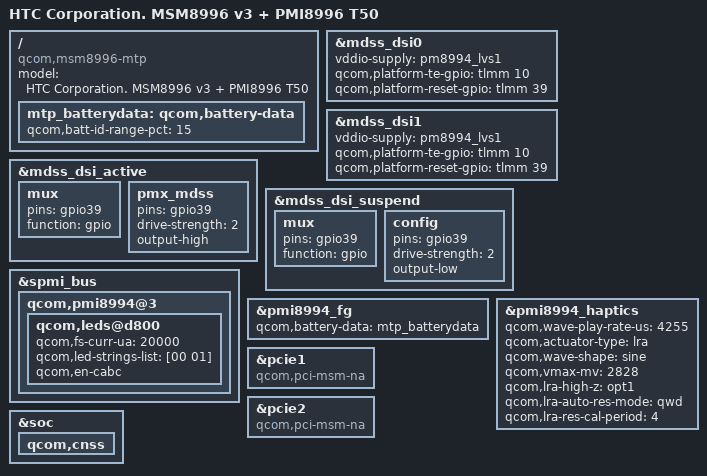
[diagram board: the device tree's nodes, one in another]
/* Copyright (c) 2015, The Linux Foundation. All rights reserved.
 *
 * This program is free software; you can redistribute it and/or modify
 * it under the terms of the GNU General Public License version 2 and
 * only version 2 as published by the Free Software Foundation.
 *
 * This program is distributed in the hope that it will be useful,
 * but WITHOUT ANY WARRANTY; without even the implied warranty of
 * MERCHANTABILITY or FITNESS FOR A PARTICULAR PURPOSE.  See the
 * GNU General Public License for more details.
 */


#include "msm8996-htc-common.dtsi"
#include "msm8996-htc-regulator.dtsi"
#include "msm8996-htc-pm.dtsi"
#include "dsi-panel-t50-hx8396c2.dtsi"
#include "dsi-panel-t50.dtsi"
#include "msm8996-touch-t50.dtsi"
#include "msm8996-key-t50.dtsi"
#include "msm8996-audio-t50.dtsi"
#include "msm8996-htc-led.dtsi"
#include "msm8996-camera-sensor-t50_xc.dtsi"
#include "msm8996-htc-nfc.dtsi"

/ {
	model = "HTC Corporation. MSM8996 v3 + PMI8996 T50";
	compatible = "qcom,msm8996-mtp", "qcom,msm8996", "qcom,mtp";
};

&mdss_dsi0 {
        vddio-supply = <&pm8994_lvs1>;

        qcom,platform-te-gpio = <&tlmm 10 0>;
        qcom,platform-reset-gpio = <&tlmm 39 0>;
        /delete-property/ qcom,platform-bklight-en-gpio;
};

&mdss_dsi1 {
        vddio-supply = <&pm8994_lvs1>;

        qcom,platform-te-gpio = <&tlmm 10 0>;
        qcom,platform-reset-gpio = <&tlmm 39 0>;
        /delete-property/ qcom,platform-bklight-en-gpio;
};

&mdss_dsi_active {
        mux {
                pins = "gpio39";
                function = "gpio";
        };

        pmx_mdss {
                pins = "gpio39";
                drive-strength = <2>; /* 2 mA */
                output-high;
        };
};

&mdss_dsi_suspend {
        mux {
                pins = "gpio39";
                function = "gpio";
        };

        config {
                pins = "gpio39";
                drive-strength = <2>; /* 2 mA */
                output-low;
        };
};

&spmi_bus {
        qcom,pmi8994@3 {
                qcom,leds@d800 {
                        qcom,fs-curr-ua = <20000>;      /* HTC: 2ch, 20mA */
                        qcom,led-strings-list = [00 01];
                        qcom,en-cabc;
                };
	};
};

/{
        mtp_batterydata: qcom,battery-data {
                qcom,batt-id-range-pct = <15>;
                #include "batterydata-s1-id1.dtsi"
                #include "batterydata-s1-id2.dtsi"
                #include "batterydata-s1-id3.dtsi"
        };
};

&pmi8994_fg {
        qcom,battery-data = <&mtp_batterydata>;
};

&pmi8994_haptics {
	status = "okay";
	qcom,wave-play-rate-us = <4255>;
	qcom,actuator-type = "lra";
	qcom,wave-shape = "sine";
	qcom,vmax-mv = <2828>;
	qcom,lra-high-z = "opt1";
	qcom,lra-auto-res-mode = "qwd";
	qcom,lra-res-cal-period = <4>;
};

&pcie1{
	compatible = "qcom,pci-msm-na";
};

&pcie2{
	compatible = "qcom,pci-msm-na";
};

&soc {
	qcom,cnss {
		/delete-property/ wlan-ant-switch-supply;
	};
};
